# SIM3L166_C register map
File version: 1
CPU: 
Registers are 32-bit, read-write, reset 0x0 unless marked. A register's access mark holds for its fields unless they carry their own. Offsets are from the block's base; [hi:lo] are bit positions.

## DMAXBAR_0
Base 0x40037000
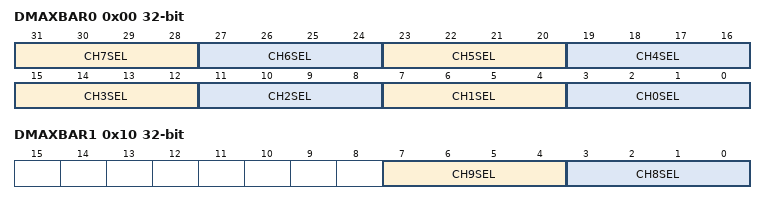
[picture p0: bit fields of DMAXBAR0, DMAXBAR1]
0x00 DMAXBAR0 — Channel 0-7 Trigger Select
  [31:28] CH7SEL — DMA Channel 7 Peripheral Select.
    0=DTM1_D (Service DTM1 D data requests.); 1=DTM2_B (Service DTM2 B data requests.); 2=ENCDEC0_RX (Service ENCDEC0 RX data requests.); 3=SPI1_TX (Service SPI1 TX data requests.); 4=USART0_RX (Service USART0 RX data requests.); 5=IDAC0 (Service IDAC0 data requests.); 6=TIMER1L (Service TIMER1L overflow data requests.); 7=TIMER1H (Service TIMER1H overflow data requests.); 8=DMA0T1_RISE (Service DMA0T1 rising edge data requests.); 9=DMA0T1_FALL (Service DMA0T1 falling edge data requests.); 15=UNASSIGNED
  [27:24] CH6SEL — DMA Channel 6 Peripheral Select.
    0=DTM1_C (Service DTM1 C data requests.); 1=DTM2_A (Service DTM2 A data requests.); 2=ENCDEC0_TX (Service ENCDEC0 TX data requests.); 3=AES0_XOR (Service AES0 XOR data requests.); 4=USART0_TX (Service USART0 TX data requests.); 5=I2C0_RX (Service I2C0 RX data requests.); 6=I2C0_TX (Service I2C0 TX data requests.); 7=SARADC0 (Service SARADC0 data requests.); 8=TIMER0L (Service TIMER0L overflow data requests.); 9=TIMER0H (Service TIMER0H overflow data requests.); 10=DMA0T0_RISE (Service DMA0T0 rising edge data requests.); 11=DMA0T0_FALL (Service DMA0T0 falling edge data requests.); 15=UNASSIGNED
  [23:20] CH5SEL — DMA Channel 5 Peripheral Select.
    0=DTM1_B (Service DTM1 B data requests.); 1=DTM2_D (Service DTM2 D data requests.); 2=SPI0_RX (Service SPI0 RX data requests.); 3=AES0_RX (Service AES0 RX data requests.); 4=USART0_RX (Service USART0 RX data requests.); 5=I2C0_RX (Service I2C0 RX data requests.); 6=IDAC0 (Service IDAC0 data requests.); 7=EPCA0_CONTROL (Service EPCA0 control data requests.); 8=TIMER1L (Service TIMER1L overflow data requests.); 9=TIMER1H (Service TIMER1H overflow data requests.); 10=DMA0T1_RISE (Service DMA0T1 rising edge data requests.); 11=DMA0T1_FALL (Service DMA0T1 falling edge data requests.); 15=UNASSIGNED
  [19:16] CH4SEL — DMA Channel 4 Peripheral Select.
    0=DTM1_A (Service DTM1 A data requests.); 1=DTM2_C (Service DTM2 C data requests.); 2=SPI0_TX (Service SPI1 TX data requests.); 3=AES0_TX (Service AES0 TX data requests.); 4=SARADC0 (Service SARADC0 data requests.); 5=EPCA0_CAPTURE (Service EPCA0 capture data requests.); 6=EPCA0_CONTROL (Service EPCA0 control data requests.); 7=TIMER0L (Service TIMER0L overflow data requests.); 8=TIMER0H (Service TIMER0H overflow data requests.); 9=DMA0T0_RISE (Service DMA0T0 rising edge data requests.); 10=DMA0T0_FALL (Service DMA0T0 falling edge data requests.); 15=UNASSIGNED
  [15:12] CH3SEL — DMA Channel 3 Peripheral Select.
    0=DTM0_D (Service DTM0 D data requests.); 1=DTM2_B (Service DTM2 B data requests.); 2=ENCDEC0_RX (Service ENCDEC0 RX data requests.); 3=SPI1_RX (Service SPI1 RX data requests.); 4=USART0_TX (Service USART0 TX data requests.); 5=I2C0_RX (Service I2C0 RX data requests.); 6=I2C0_TX (Service I2C0 TX data requests.); 7=TIMER1L (Service TIMER1L overflow data requests.); 8=TIMER1H (Service TIMER1H overflow data requests.); 9=DMA0T1_RISE (Service DMA0T1 rising edge data requests.); 10=DMA0T1_FALL (Service DMA0T1 falling edge data requests.); 15=UNASSIGNED
  [11:8] CH2SEL — DMA Channel 2 Peripheral Select.
    0=DTM0_C (Service DTM0 C data requests.); 1=DTM2_A (Service DTM2 A data requests.); 2=ENCDEC0_TX (Service ENCDEC0 TX data requests.); 3=AES0_XOR (Service AES0 XOR data requests.); 4=SPI1_TX (Service SPI1 TX data requests.); 5=USART0_RX (Service USART0 RX data requests.); 6=I2C0_RX (Service I2C0 RX data requests.); 7=IDAC0 (Service IDAC0 data requests.); 8=TIMER0L (Service TIMER0L overflow data requests.); 9=TIMER0H (Service TIMER0H overflow data requests.); 10=DMA0T0_RISE (Service DMA0T0 rising edge data requests.); 11=DMA0T0_FALL (Service DMA0T0 falling edge data requests.); 15=UNASSIGNED
  [7:4] CH1SEL — DMA Channel 1 Peripheral Select.
    0=DTM0_B (Service DTM0 B data requests.); 1=SPI0_RX (Service SPI0 RX data requests.); 2=AES0_RX (Service AES0 RX data requests.); 3=USART0_TX (Service USART0 TX data requests.); 4=SARADC0 (Service SARADC0 data requests.); 5=EPCA0_CAPTURE (Service EPCA0 capture data requests.); 6=EPCA0_CONTROL (Service EPCA0 control data requests.); 7=TIMER1L (Service TIMER1L overflow data requests.); 8=TIMER1H (Service TIMER1H overflow data requests.); 9=DMA0T1_RISE (Service DMA0T1 rising edge data requests.); 10=DMA0T1_FALL (Service DMA0T1 falling edge data requests.); 15=UNASSIGNED
  [3:0] CH0SEL — DMA Channel 0 Peripheral Select.
    0=DTM0_A (Service DTM0 A data requests.); 1=SPI0_TX (Service SPI0 TX data requests.); 2=AES0_TX (Service AES0 TX data requests.); 3=USART0_RX (Service USART0 RX data requests.); 4=I2C0_RX (Service I2C0 RX data requests.); 5=I2C0_TX (Service I2C0 TX data requests.); 6=EPCA0_CAPTURE (Service EPCA0 capture data requests.); 7=TIMER0L (Service TIMER0L overflow data requests.); 8=TIMER0H (Service TIMER0H overflow data requests.); 9=DMA0T0_RISE (Service DMA0T0 rising edge data requests.); 10=DMA0T0_FALL (Service DMA0T0 falling edge data requests.); 15=UNASSIGNED
0x10 DMAXBAR1 — Channel 8-15 Trigger Select
  [7:4] CH9SEL — DMA Channel 9 Peripheral Select.
    0=DTM2_D (Service DTM2 D data requests.); 1=SPI0_RX (Service SPI0 TX data requests.); 2=I2C0_RX (Service I2C0 RX data requests.); 3=I2C0_TX (Service I2C0 TX data requests.); 4=IDAC0 (Service IDAC0 data requests.); 5=EPCA0_CAPTURE (Service EPCA0 capture data requests.); 6=EPCA0_CONTROL (Service EPCA0 control data requests.); 7=TIMER1L (Service TIMER1L overflow data requests.); 8=TIMER1H (Service TIMER1H overflow data requests.); 9=DMA0T1_RISE (Service DMA0T1 rising edge data requests.); 10=DMA0T1_FALL (Service DMA0T1 falling edge data requests.); 15=UNASSIGNED
  [3:0] CH8SEL — DMA Channel 8 Peripheral Select.
    0=DTM2_C (Service DTM2 C data requests.); 1=SPI0_TX (Service SPI0 TX data requests.); 2=SPI1_RX (Service SPI1 RX data requests.); 3=USART0_TX (Service USART0 TX data requests.); 4=I2C0_RX (Service I2C0 RX data requests.); 5=SARADC0 (Service SARADC0 data requests.); 6=EPCA0_CAPTURE (Service EPCA0 capture data requests.); 7=TIMER0L (Service TIMER0L overflow data requests.); 8=TIMER0H (Service TIMER0H overflow data requests.); 9=DMA0T0_RISE (Service DMA0T0 rising edge data requests.); 10=DMA0T0_FALL (Service DMA0T0 falling edge data requests.); 15=UNASSIGNED
